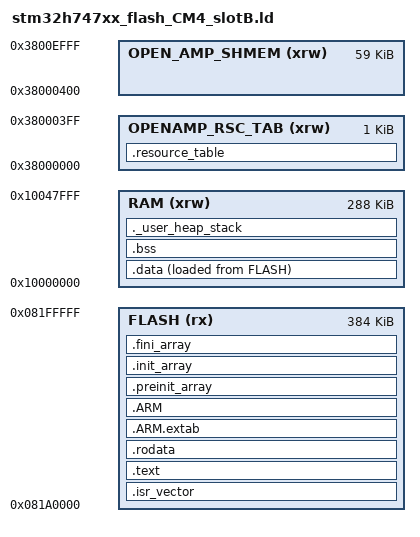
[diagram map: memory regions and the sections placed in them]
/*
 * CM4 APP Slot B @ 0x081A0000, 384KB
 */
ENTRY(Reset_Handler)

_estack = 0x10048000;
_Min_Heap_Size = 0x200;
_Min_Stack_Size = 0x400;

MEMORY
{
FLASH (rx)      : ORIGIN = 0x081A0000, LENGTH = 384K
RAM (xrw)       : ORIGIN = 0x10000000, LENGTH = 288K
OPENAMP_RSC_TAB (xrw) : ORIGIN = 0x38000000, LENGTH = 1K
OPEN_AMP_SHMEM (xrw) : ORIGIN = 0x38000400, LENGTH = 59K
}

__OPENAMP_region_start__ = ORIGIN(OPEN_AMP_SHMEM);
__OPENAMP_region_end__ = ORIGIN(OPEN_AMP_SHMEM) + LENGTH(OPEN_AMP_SHMEM);

SECTIONS
{
  .isr_vector :
  {
    . = ALIGN(4);
    KEEP(*(.isr_vector))
    . = ALIGN(4);
  } >FLASH

  .text :
  {
    . = ALIGN(4);
    *(.text)
    *(.text*)
    *(.glue_7)
    *(.glue_7t)
    *(.eh_frame)
    KEEP (*(.init))
    KEEP (*(.fini))
    . = ALIGN(4);
    _etext = .;
  } >FLASH

  .rodata :
  {
    . = ALIGN(4);
    *(.rodata)
    *(.rodata*)
    . = ALIGN(4);
  } >FLASH

  .ARM.extab (READONLY) :
  {
    *(.ARM.extab* .gnu.linkonce.armextab.*)
  } >FLASH

  .ARM (READONLY) :
  {
    __exidx_start = .;
    *(.ARM.exidx*)
    __exidx_end = .;
  } >FLASH

  .preinit_array (READONLY) :
  {
    PROVIDE_HIDDEN (__preinit_array_start = .);
    KEEP (*(.preinit_array*))
    PROVIDE_HIDDEN (__preinit_array_end = .);
  } >FLASH

  .init_array (READONLY) :
  {
    PROVIDE_HIDDEN (__init_array_start = .);
    KEEP (*(SORT(.init_array.*)))
    KEEP (*(.init_array*))
    PROVIDE_HIDDEN (__init_array_end = .);
  } >FLASH

  .fini_array (READONLY) :
  {
    PROVIDE_HIDDEN (__fini_array_start = .);
    KEEP (*(SORT(.fini_array.*)))
    KEEP (*(.fini_array*))
    PROVIDE_HIDDEN (__fini_array_end = .);
  } >FLASH

  .resource_table (NOLOAD) :
  {
    . = ALIGN(4);
    KEEP(*(.resource_table))
    . = ALIGN(4);
  } >OPENAMP_RSC_TAB

  _sidata = LOADADDR(.data);

  .data :
  {
    . = ALIGN(4);
    _sdata = .;
    *(.data)
    *(.data*)
    . = ALIGN(4);
    _edata = .;
  } >RAM AT> FLASH

  . = ALIGN(4);
  .bss :
  {
    _sbss = .;
    __bss_start__ = _sbss;
    *(.bss)
    *(.bss*)
    *(COMMON)
    . = ALIGN(4);
    _ebss = .;
    __bss_end__ = _ebss;
  } >RAM

  ._user_heap_stack :
  {
    . = ALIGN(8);
    PROVIDE ( end = . );
    PROVIDE ( _end = . );
    . = . + _Min_Heap_Size;
    . = . + _Min_Stack_Size;
    . = ALIGN(8);
  } >RAM

  /DISCARD/ :
  {
    libc.a ( * )
    libm.a ( * )
    libgcc.a ( * )
  }

  .ARM.attributes 0 : { *(.ARM.attributes) }
}
